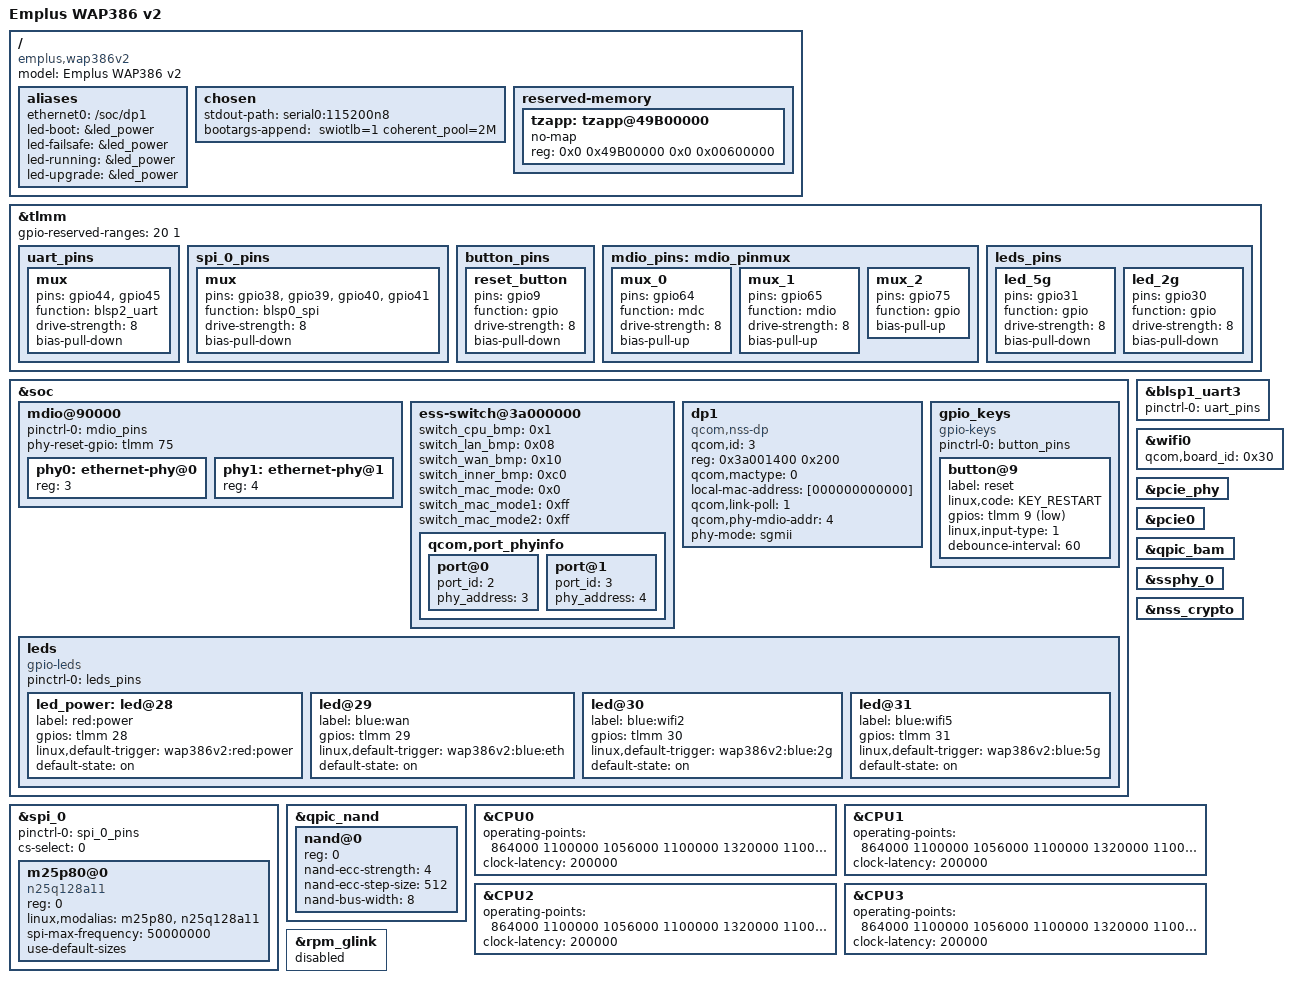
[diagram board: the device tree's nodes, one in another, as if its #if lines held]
/*
 * Copyright (c) 2019-2021, The Linux Foundation. All rights reserved.
 *
 * Permission to use, copy, modify, and/or distribute this software for any
 * purpose with or without fee is hereby granted, provided that the above
 * copyright notice and this permission notice appear in all copies.
 *
 * THE SOFTWARE IS PROVIDED "AS IS" AND THE AUTHOR DISCLAIMS ALL WARRANTIES
 * WITH REGARD TO THIS SOFTWARE INCLUDING ALL IMPLIED WARRANTIES OF
 * MERCHANTABILITY AND FITNESS. IN NO EVENT SHALL THE AUTHOR BE LIABLE FOR
 * ANY SPECIAL, DIRECT, INDIRECT, OR CONSEQUENTIAL DAMAGES OR ANY DAMAGES
 * WHATSOEVER RESULTING FROM LOSS OF USE, DATA OR PROFITS, WHETHER IN AN
 * ACTION OF CONTRACT, NEGLIGENCE OR OTHER TORTIOUS ACTION, ARISING OUT OF
 * OR IN CONNECTION WITH THE USE OR PERFORMANCE OF THIS SOFTWARE.
 */

/dts-v1/;

#include "ipq6018.dtsi"
#include "ipq6018-cpr-regulator.dtsi"
#include <dt-bindings/input/input.h>

/ {
	model = "Emplus WAP386 v2";
	compatible = "emplus,wap386v2", "qcom,ipq6018-cp03", "qcom,ipq6018";

	aliases {
		/*
		 * Aliases as required by u-boot
		 * to patch MAC addresses
		 */
		ethernet0 = "/soc/dp1";

		led-boot = &led_power;
		led-failsafe = &led_power;
		led-running = &led_power;
		led-upgrade = &led_power;
	};

	chosen {
		stdout-path = "serial0:115200n8";
		bootargs-append = " swiotlb=1 coherent_pool=2M";
	};

	/*
	 * +=========+==============+========================+
	 * |        |              |                         |
	 * | Region | Start Offset |          Size           |
	 * |        |              |                         |
	 * +--------+--------------+-------------------------+
	 * |        |              |                         |
	 * |        |              |                         |
	 * |        |              |                         |
	 * |        |              |                         |
	 * | Linux  |  0x41000000  |         139MB           |
	 * |        |              |                         |
	 * |        |              |                         |
	 * |        |              |                         |
	 * +--------+--------------+-------------------------+
	 * | TZ App |  0x49B00000  |           6MB           |
	 * +--------+--------------+-------------------------+
	 *
	 * From the available 145 MB for Linux in the first 256 MB,
	 * we are reserving 6 MB for TZAPP.
	 *
	 * Refer arch/arm64/boot/dts/qcom/qcom-ipq6018-memory.dtsi
	 * for memory layout.
	 */

/* TZAPP is enabled only in default memory profile */
#if !defined(__IPQ_MEM_PROFILE_256_MB__) && !defined(__IPQ_MEM_PROFILE_512_MB__)
	reserved-memory {
		tzapp:tzapp@49B00000 {	/* TZAPPS */
			no-map;
			reg = <0x0 0x49B00000 0x0 0x00600000>;
		};
	};
#endif
};

&tlmm {
	gpio-reserved-ranges = <20 1>;

	uart_pins: uart_pins {
		mux {
			pins = "gpio44", "gpio45";
			function = "blsp2_uart";
			drive-strength = <8>;
			bias-pull-down;
		};
	};

	spi_0_pins: spi_0_pins {
		mux {
			pins = "gpio38", "gpio39", "gpio40", "gpio41";
			function = "blsp0_spi";
			drive-strength = <8>;
			bias-pull-down;
		};
	};

	button_pins: button_pins {
		reset_button {
			pins = "gpio9";
			function = "gpio";
			drive-strength = <8>;
			bias-pull-down;
		};
	};

	mdio_pins: mdio_pinmux {
		mux_0 {
			pins = "gpio64";
			function = "mdc";
			drive-strength = <8>;
			bias-pull-up;
		};
		mux_1 {
			pins = "gpio65";
			function = "mdio";
			drive-strength = <8>;
			bias-pull-up;
		};
		mux_2 {
			pins = "gpio75";
			function = "gpio";
			bias-pull-up;
		};
	};

	leds_pins: leds_pins {
		led_5g {
			pins = "gpio31";
			function = "gpio";
			drive-strength = <8>;
			bias-pull-down;
		};
		led_2g {
			pins = "gpio30";
			function = "gpio";
			drive-strength = <8>;
			bias-pull-down;
		};
	};
};

&soc {
	mdio@90000 {
		pinctrl-0 = <&mdio_pins>;
		pinctrl-names = "default";
		phy-reset-gpio = <&tlmm 75 0>;
		status = "ok";
		phy0: ethernet-phy@0 {
			reg = <3>;
		};
		phy1: ethernet-phy@1 {
			reg = <4>;
		};
	};

	ess-switch@3a000000 {
		switch_cpu_bmp = <0x1>;  /* cpu port bitmap */
		switch_lan_bmp = <0x08>; /* lan port bitmap */
		switch_wan_bmp = <0x10>; /* wan port bitmap */
		switch_inner_bmp = <0xc0>; /*inner port bitmap*/
		switch_mac_mode = <0x0>; /* mac mode for uniphy instance0*/
		switch_mac_mode1 = <0xff>; /* mac mode for uniphy instance1*/
		switch_mac_mode2 = <0xff>; /* mac mode for uniphy instance2*/
		qcom,port_phyinfo {
			port@0 {
				port_id = <2>;
				phy_address = <3>;
			};
			port@1 {
				port_id = <3>;
				phy_address = <4>;
			};
		};
	};

	dp1 {
		device_type = "network";
		compatible = "qcom,nss-dp";
		qcom,id = <3>;
		reg = <0x3a001400 0x200>;
		qcom,mactype = <0>;
		local-mac-address = [000000000000];
		qcom,link-poll = <1>;
		qcom,phy-mdio-addr = <4>;
		phy-mode = "sgmii";
	};

	gpio_keys {
		compatible = "gpio-keys";
		pinctrl-0 = <&button_pins>;
		pinctrl-names = "default";

		button@9 {
			label = "reset";
			linux,code = <KEY_RESTART>;
			gpios = <&tlmm 9 GPIO_ACTIVE_LOW>;
			linux,input-type = <1>;
			debounce-interval = <60>;
		};
	};

	leds {
		compatible = "gpio-leds";
		pinctrl-0 = <&leds_pins>;
		pinctrl-names = "default";

		led_power: led@28 {
			label = "red:power";
			gpios = <&tlmm 28 GPIO_ACTIVE_HIGH>;
			linux,default-trigger = "wap386v2:red:power";
			default-state = "on";
		};
		led@29 {
			label = "blue:wan";
			gpios = <&tlmm 29 GPIO_ACTIVE_HIGH>;
			linux,default-trigger = "wap386v2:blue:eth";
			default-state = "on";
		};
		led@30 {
			label = "blue:wifi2";
			gpios = <&tlmm 30 GPIO_ACTIVE_HIGH>;
			linux,default-trigger = "wap386v2:blue:2g";
			default-state = "on";
		};
		led@31 {
			label = "blue:wifi5";
			gpios = <&tlmm 31 GPIO_ACTIVE_HIGH>;
			linux,default-trigger = "wap386v2:blue:5g";
			default-state = "on";
		};
	};
};

&blsp1_uart3 {
	pinctrl-0 = <&uart_pins>;
	pinctrl-names = "default";
	status = "ok";
};

&spi_0 {
	pinctrl-0 = <&spi_0_pins>;
	pinctrl-names = "default";
	cs-select = <0>;
	status = "ok";

	m25p80@0 {
		#address-cells = <1>;
		#size-cells = <1>;
		reg = <0>;
		compatible = "n25q128a11";
		linux,modalias = "m25p80", "n25q128a11";
		spi-max-frequency = <50000000>;
		use-default-sizes;
	};
};

&wifi0 {
	qcom,board_id = <0x30>;
};

&pcie_phy {
	status = "ok";
};

&pcie0 {
#if defined(__CNSS2__)
	status = "ok";
#endif
};

&qpic_bam {
	status = "ok";
};

&qpic_nand {
	status = "ok";

	nand@0 {
		reg = <0>;
		#address-cells = <1>;
		#size-cells = <1>;

		nand-ecc-strength = <4>;
		nand-ecc-step-size = <512>;
		nand-bus-width = <8>;
	};
};

&ssphy_0 {
	status = "ok";
};

&nss_crypto {
	status = "ok";
};

&CPU0 {
	operating-points = <
		/* kHz   uV (fixed) */
		864000   1100000
		1056000  1100000
		1320000  1100000
		1440000  1100000
		1608000  1100000
		1800000  1100000
	>;
	clock-latency = <200000>;
};

&CPU1 {
	operating-points = <
		/* kHz   uV (fixed) */
		864000   1100000
		1056000  1100000
		1320000  1100000
		1440000  1100000
		1608000  1100000
		1800000  1100000
	>;
	clock-latency = <200000>;
};

&CPU2 {
	operating-points = <
		/* kHz   uV (fixed) */
		864000   1100000
		1056000  1100000
		1320000  1100000
		1440000  1100000
		1608000  1100000
		1800000  1100000
	>;
	clock-latency = <200000>;
};

&CPU3 {
	operating-points = <
		/* kHz   uV (fixed) */
		864000   1100000
		1056000  1100000
		1320000  1100000
		1440000  1100000
		1608000  1100000
		1800000  1100000
	>;
	clock-latency = <200000>;
};

&rpm_glink {
	status = "disabled";
};
